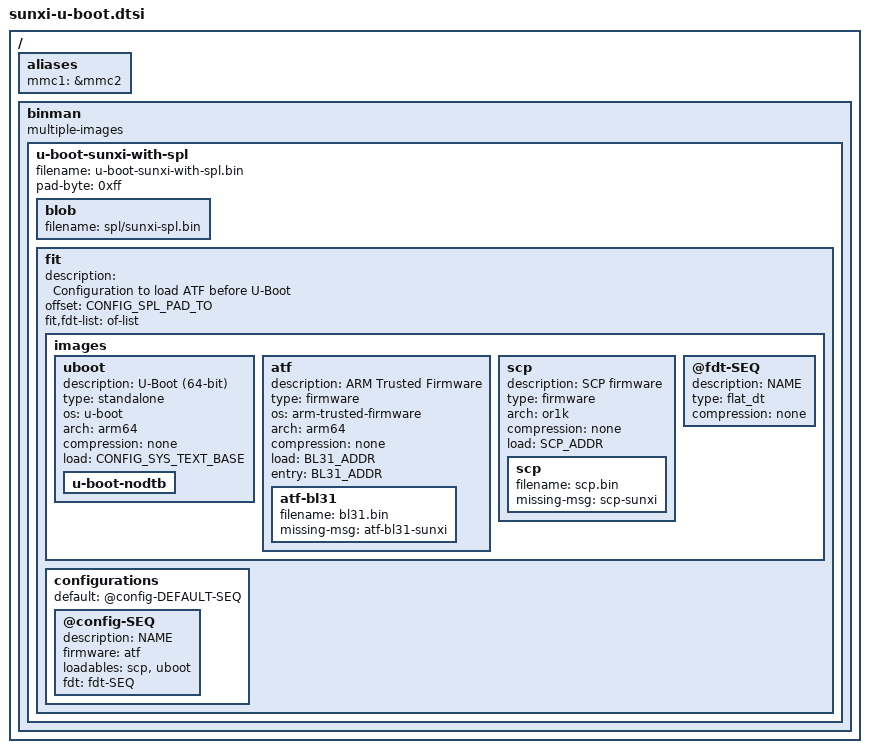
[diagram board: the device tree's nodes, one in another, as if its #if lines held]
#include <config.h>

#ifdef CONFIG_ARM64
#ifdef CONFIG_MACH_SUN50I_H6
#define BL31_ADDR 0x104000
#define  SCP_ADDR 0x114000
#else
#define BL31_ADDR  0x44000
#define  SCP_ADDR  0x50000
#endif
#else
#define  SCP_ADDR  0x48000
#endif

/ {
	aliases {
		mmc1 = &mmc2;
	};

	binman: binman {
		multiple-images;
	};
};

&binman {
	u-boot-sunxi-with-spl {
		filename = "u-boot-sunxi-with-spl.bin";
		pad-byte = <0xff>;

		blob {
			filename = "spl/sunxi-spl.bin";
		};

#ifdef CONFIG_SPL_FIT
#ifdef CONFIG_ARM64
		fit {
			description = "Configuration to load ATF before U-Boot";
			offset = <CONFIG_SPL_PAD_TO>;
			#address-cells = <1>;
			fit,fdt-list = "of-list";

			images {
				uboot {
					description = "U-Boot (64-bit)";
					type = "standalone";
					os = "u-boot";
					arch = "arm64";
					compression = "none";
					load = <CONFIG_SYS_TEXT_BASE>;

					u-boot-nodtb {
					};
				};

				atf {
					description = "ARM Trusted Firmware";
					type = "firmware";
					os = "arm-trusted-firmware";
					arch = "arm64";
					compression = "none";
					load = <BL31_ADDR>;
					entry = <BL31_ADDR>;

					atf-bl31 {
						filename = "bl31.bin";
						missing-msg = "atf-bl31-sunxi";
					};
				};

				scp {
					description = "SCP firmware";
					type = "firmware";
					arch = "or1k";
					compression = "none";
					load = <SCP_ADDR>;

					scp {
						filename = "scp.bin";
						missing-msg = "scp-sunxi";
					};
				};

				@fdt-SEQ {
					description = "NAME";
					type = "flat_dt";
					compression = "none";
				};
			};

			configurations {
				default = "@config-DEFAULT-SEQ";

				@config-SEQ {
					description = "NAME";
					firmware = "atf";
					loadables = "scp", "uboot";
					fdt = "fdt-SEQ";
				};
			};
		};
#else
		fit {
			description = "Configuration to load SCP firmware with U-Boot";
			offset = <CONFIG_SPL_PAD_TO>;
			#address-cells = <1>;
			fit,fdt-list = "of-list";

			images {
				uboot {
					description = "U-Boot (32-bit)";
					type = "standalone";
					os = "u-boot";
					arch = "arm";
					compression = "none";
					load = <CONFIG_SYS_TEXT_BASE>;

					u-boot-nodtb {
					};
				};

				scp {
					description = "SCP firmware";
					type = "firmware";
					arch = "or1k";
					compression = "none";
					load = <SCP_ADDR>;

					scp {
						filename = "scp.bin";
						missing-msg = "scp-sunxi";
					};
				};

				@fdt-SEQ {
					description = "NAME";
					type = "flat_dt";
					compression = "none";

				};
			};

			configurations {
				default = "@config-DEFAULT-SEQ";

				@config-SEQ {
					description = "NAME";
					firmware = "uboot";
					loadables = "scp";
					fdt = "fdt-SEQ";
				};
			};
		};
#endif
#else
		u-boot-img {
			offset = <CONFIG_SPL_PAD_TO>;
		};
#endif
	};
};
